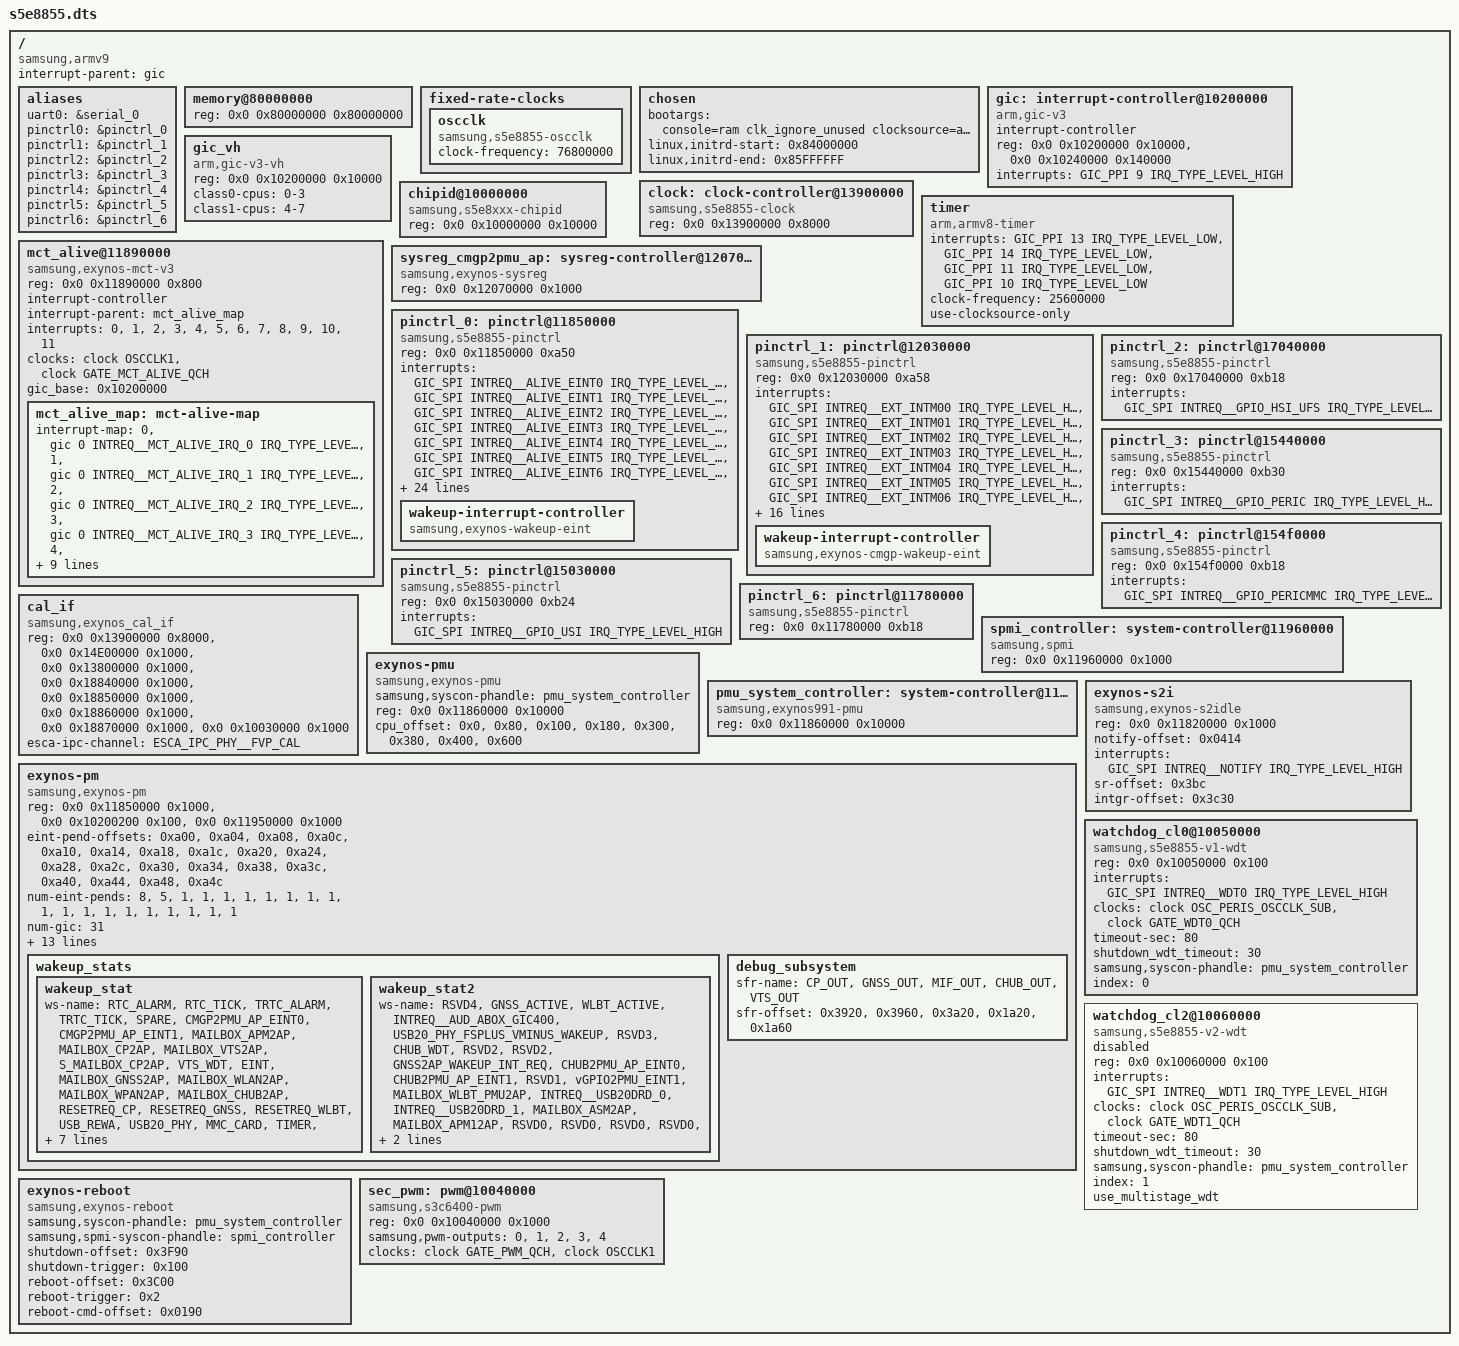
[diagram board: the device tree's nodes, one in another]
/*
 * SAMSUNG S5E8855 SoC device tree source
 *
 * Copyright (c) 2023 Samsung Electronics Co., Ltd.
 *             http://www.samsung.com
 *
 * SAMSUNG S5E8855 SoC device nodes are listed in this file.
 * EXYNOS based board files can include this file and provide
 * values for board specfic bindings.
 *
 * This program is free software; you can redistribute it and/or modify
 * it under the terms of the GNU General Public License version 2 as
 * published by the Free Software Foundation.
 */

/dts-v1/;
/plugin/;
#include <dt-bindings/clock/s5e8855.h>
#include <dt-bindings/interrupt-controller/s5e8855.h>
#include "s5e8855-pm-domains.dtsi"
#include "s5e8855-esca.dtsi"
#include <dt-bindings/soc/samsung/s5e8855-dm.h>
#include <dt-bindings/soc/samsung/s5e8855-devfreq.h>
#include <dt-bindings/soc/samsung/exynos_pm_qos.h>
//#include <dt-bindings/soc/samsung/exynos-bcm_dbg.h>
#include "s5e8855-usi.dtsi"
#include "s5e8855-pinctrl.dtsi"
#include "s5e8855-cpu.dtsi"
#include "s5e8855-ems.dtsi"
#include "s5e8855-xperf.dtsi"
#include "s5e8855-sysmmu.dtsi"
#include "s5e8855-sgpu.dtsi"
#include "s5e8855-drm-dpu.dtsi"
#include "s5e8855-usb.dtsi"
#include "s5e8855-ufs.dtsi"
#include "s5e8855-debug.dtsi"
#include "s5e8855-rmem.dtsi"
#include "s5e8855-dma-heap.dtsi"
#include "s5e8855-power.dtsi"
#include "s5e8855-security.dtsi"
#include "s5e8855-mmc.dtsi"
#include "s5e8855-m2m.dtsi"
#include "s5e8855-wlbt.dtsi"
#include "s5e8855-mfc.dtsi"
#include "s5e8855-audio.dtsi"
#include "s5e8855-chub.dtsi"
#include "s5e8855-npu.dtsi"
#include "s5e8855-camera.dtsi"
#include "s5e8855-uarch.dtsi"
#include "s5e8855-profiler.dtsi"
#include "s5e8855-mifgov.dtsi"

/ {
	compatible = "samsung,armv9", "samsung,s5e8855";
	interrupt-parent = <&gic>;
	#address-cells = <2>;
	#size-cells = <1>;

	aliases {
		uart0 = &serial_0;
		pinctrl0 = &pinctrl_0;
		pinctrl1 = &pinctrl_1;
		pinctrl2 = &pinctrl_2;
		pinctrl3 = &pinctrl_3;
		pinctrl4 = &pinctrl_4;
		pinctrl5 = &pinctrl_5;
		pinctrl6 = &pinctrl_6;
	};

	memory@80000000 {
                device_type = "memory";
                reg = <0x0 0x80000000 0x80000000>;
	};

	fixed-rate-clocks {
		oscclk {
			compatible = "samsung,s5e8855-oscclk";
			clock-frequency = <76800000>;
		};
	};

	chosen: chosen {
		bootargs = "console=ram clk_ignore_unused clocksource=arch_sys_counter printk.devkmsg=on arm64.nomte rcupdate.rcu_expedited=1 swiotlb=noforce s3c2410_wdt_ext.tmr_atboot=1 firmware_class.path=/vendor/firmware cpufreq.default_governor=energy_aware kvm-arm.protected_modules=exynos-pkvm-module,exynos-pkvm-s2mpu-module restrict_cma_redirect loop.max_part=7 memblock_memsize=procfs fault_around_bytes=32768 kswapd_cpumask=0x7f kcompactd_cpumask=0x7f raise_min_free_kbytes=false transparent_hugepage=never cgroup.memory=nokmem sgpu.gfx_timeout=10000 sgpu.mcbp=0";
		linux,initrd-start = <0x84000000>;
		linux,initrd-end = <0x85FFFFFF>;
	};

	gic:interrupt-controller@10200000 {
			compatible = "arm,gic-v3";
			#interrupt-cells = <3>;
			interrupt-controller;
			reg = <0x0 0x10200000 0x10000>,         /* GICD */
				  <0x0 0x10240000 0x140000>;        /* GICR * 10 */
			interrupts = <GIC_PPI 9 IRQ_TYPE_LEVEL_HIGH>;
	};

	gic_vh: gic_vh {
			compatible = "arm,gic-v3-vh";
			reg = <0x0 0x10200000 0x10000>;		/* GICD */
			class0-cpus = "0-3";
			class1-cpus = "4-7";
	};

	clock: clock-controller@13900000 {
		compatible = "samsung,s5e8855-clock";
		reg = <0x0 0x13900000 0x8000>;
		#clock-cells = <1>;
	};

	chipid@10000000 {
		compatible = "samsung,s5e8xxx-chipid";
		reg = <0x0 0x10000000 0x10000>;
	};

	timer {
		compatible = "arm,armv8-timer";
		interrupts = <GIC_PPI 13 IRQ_TYPE_LEVEL_LOW>,
			     <GIC_PPI 14 IRQ_TYPE_LEVEL_LOW>,
			     <GIC_PPI 11 IRQ_TYPE_LEVEL_LOW>,
			     <GIC_PPI 10 IRQ_TYPE_LEVEL_LOW>;
		clock-frequency = <25600000>;
		use-clocksource-only;
	};

	mct_alive@11890000 {
			compatible = "samsung,exynos-mct-v3";
			reg = <0x0 0x11890000 0x800>;
			interrupt-controller;
			#interrupt-cells = <1>;
			interrupt-parent = <&mct_alive_map>;
			interrupts =    <0>, <1>, <2>, <3>,
							<4>, <5>, <6>, <7>,
							<8>, <9>, <10>, <11>;
			clocks = <&clock OSCCLK1>, <&clock GATE_MCT_ALIVE_QCH>;
			clock-names = "fin_pll", "mct";
			gic_base = <0x10200000>;

			mct_alive_map: mct-alive-map {
					#interrupt-cells = <1>;
					#address-cells = <0>;
					#size-cells = <0>;
					interrupt-map = <0 &gic 0 INTREQ__MCT_ALIVE_IRQ_0 IRQ_TYPE_LEVEL_HIGH>,
							<1 &gic 0 INTREQ__MCT_ALIVE_IRQ_1 IRQ_TYPE_LEVEL_HIGH>,
							<2 &gic 0 INTREQ__MCT_ALIVE_IRQ_2 IRQ_TYPE_LEVEL_HIGH>,
							<3 &gic 0 INTREQ__MCT_ALIVE_IRQ_3 IRQ_TYPE_LEVEL_HIGH>,
							<4 &gic 0 INTREQ__MCT_ALIVE_IRQ_4 IRQ_TYPE_LEVEL_HIGH>,
							<5 &gic 0 INTREQ__MCT_ALIVE_IRQ_5 IRQ_TYPE_LEVEL_HIGH>,
							<6 &gic 0 INTREQ__MCT_ALIVE_IRQ_6 IRQ_TYPE_LEVEL_HIGH>,
							<7 &gic 0 INTREQ__MCT_ALIVE_IRQ_7 IRQ_TYPE_LEVEL_HIGH>,
							<8 &gic 0 INTREQ__MCT_ALIVE_IRQ_8 IRQ_TYPE_LEVEL_HIGH>;
			};
	};

        sysreg_cmgp2pmu_ap: sysreg-controller@12070000 {
		compatible = "samsung,exynos-sysreg", "syscon";
		reg = <0x0 0x12070000 0x1000>;
	};

	/* ALIVE */
	pinctrl_0: pinctrl@11850000 {
		compatible = "samsung,s5e8855-pinctrl";
		reg = <0x0 0x11850000 0xa50>;
		interrupts = <GIC_SPI INTREQ__ALIVE_EINT0 IRQ_TYPE_LEVEL_HIGH>,
				<GIC_SPI INTREQ__ALIVE_EINT1 IRQ_TYPE_LEVEL_HIGH>,
				<GIC_SPI INTREQ__ALIVE_EINT2 IRQ_TYPE_LEVEL_HIGH>,
				<GIC_SPI INTREQ__ALIVE_EINT3 IRQ_TYPE_LEVEL_HIGH>,
				<GIC_SPI INTREQ__ALIVE_EINT4 IRQ_TYPE_LEVEL_HIGH>,
				<GIC_SPI INTREQ__ALIVE_EINT5 IRQ_TYPE_LEVEL_HIGH>,
				<GIC_SPI INTREQ__ALIVE_EINT6 IRQ_TYPE_LEVEL_HIGH>,
				<GIC_SPI INTREQ__ALIVE_EINT7 IRQ_TYPE_LEVEL_HIGH>,
				<GIC_SPI INTREQ__ALIVE_EINT8 IRQ_TYPE_LEVEL_HIGH>,
				<GIC_SPI INTREQ__ALIVE_EINT9 IRQ_TYPE_LEVEL_HIGH>,
				<GIC_SPI INTREQ__ALIVE_EINT10 IRQ_TYPE_LEVEL_HIGH>,
				<GIC_SPI INTREQ__ALIVE_EINT11 IRQ_TYPE_LEVEL_HIGH>,
				<GIC_SPI INTREQ__ALIVE_EINT12 IRQ_TYPE_LEVEL_HIGH>,
				<GIC_SPI INTREQ__ALIVE_EXT_INTC0 IRQ_TYPE_LEVEL_HIGH>,
				<GIC_SPI INTREQ__ALIVE_EXT_INTC1 IRQ_TYPE_LEVEL_HIGH>,
				<GIC_SPI INTREQ__ALIVE_EXT_INTC2 IRQ_TYPE_LEVEL_HIGH>,
				<GIC_SPI INTREQ__ALIVE_EXT_INTC3 IRQ_TYPE_LEVEL_HIGH>,
				<GIC_SPI INTREQ__ALIVE_EXT_INTC4 IRQ_TYPE_LEVEL_HIGH>,
				<GIC_SPI INTREQ__ALIVE_EXT_INTC5 IRQ_TYPE_LEVEL_HIGH>,
				<GIC_SPI INTREQ__ALIVE_EXT_INTC6 IRQ_TYPE_LEVEL_HIGH>,
				<GIC_SPI INTREQ__ALIVE_EXT_INTC7 IRQ_TYPE_LEVEL_HIGH>,
				<GIC_SPI INTREQ__ALIVE_EXT_INTC8 IRQ_TYPE_LEVEL_HIGH>,
				<GIC_SPI INTREQ__ALIVE_EXT_INTC9 IRQ_TYPE_LEVEL_HIGH>,
				<GIC_SPI INTREQ__ALIVE_EXT_INTC10 IRQ_TYPE_LEVEL_HIGH>,
				<GIC_SPI INTREQ__ALIVE_EXT_INTC11 IRQ_TYPE_LEVEL_HIGH>,
				<GIC_SPI INTREQ__ALIVE_EXT_INTC12 IRQ_TYPE_LEVEL_HIGH>,
				<GIC_SPI INTREQ__ALIVE_EXT_INTC13 IRQ_TYPE_LEVEL_HIGH>,
				<GIC_SPI INTREQ__ALIVE_EXT_INTC14 IRQ_TYPE_LEVEL_HIGH>,
				<GIC_SPI INTREQ__ALIVE_EXT_INTC15 IRQ_TYPE_LEVEL_HIGH>,
				<GIC_SPI INTREQ__ALIVE_EXT_INTC16 IRQ_TYPE_LEVEL_HIGH>,
				<GIC_SPI INTREQ__ALIVE_EXT_INTC17 IRQ_TYPE_LEVEL_HIGH>;

		wakeup-interrupt-controller {
			compatible = "samsung,exynos-wakeup-eint";
		};
	};

	/* CMGP */
	pinctrl_1: pinctrl@12030000{
		compatible = "samsung,s5e8855-pinctrl";
		reg = <0x0 0x12030000 0xa58>;
		interrupts =
				<GIC_SPI INTREQ__EXT_INTM00 IRQ_TYPE_LEVEL_HIGH>,
				<GIC_SPI INTREQ__EXT_INTM01 IRQ_TYPE_LEVEL_HIGH>,
				<GIC_SPI INTREQ__EXT_INTM02 IRQ_TYPE_LEVEL_HIGH>,
				<GIC_SPI INTREQ__EXT_INTM03 IRQ_TYPE_LEVEL_HIGH>,
				<GIC_SPI INTREQ__EXT_INTM04 IRQ_TYPE_LEVEL_HIGH>,
				<GIC_SPI INTREQ__EXT_INTM05 IRQ_TYPE_LEVEL_HIGH>,
				<GIC_SPI INTREQ__EXT_INTM06 IRQ_TYPE_LEVEL_HIGH>,
				<GIC_SPI INTREQ__EXT_INTM07 IRQ_TYPE_LEVEL_HIGH>,
				<GIC_SPI INTREQ__EXT_INTM08 IRQ_TYPE_LEVEL_HIGH>,
				<GIC_SPI INTREQ__EXT_INTM09 IRQ_TYPE_LEVEL_HIGH>,
				<GIC_SPI INTREQ__EXT_INTM10 IRQ_TYPE_LEVEL_HIGH>,
				<GIC_SPI INTREQ__EXT_INTM11 IRQ_TYPE_LEVEL_HIGH>,
				<GIC_SPI INTREQ__EXT_INTM12 IRQ_TYPE_LEVEL_HIGH>,
				<GIC_SPI INTREQ__EXT_INTM13 IRQ_TYPE_LEVEL_HIGH>,
				<GIC_SPI INTREQ__EXT_INTM14 IRQ_TYPE_LEVEL_HIGH>,
				<GIC_SPI INTREQ__EXT_INTM15 IRQ_TYPE_LEVEL_HIGH>,
				<GIC_SPI INTREQ__EXT_INTM16 IRQ_TYPE_LEVEL_HIGH>,
				<GIC_SPI INTREQ__EXT_INTM17 IRQ_TYPE_LEVEL_HIGH>,
				<GIC_SPI INTREQ__EXT_INTM18 IRQ_TYPE_LEVEL_HIGH>,
				<GIC_SPI INTREQ__EXT_INTM19 IRQ_TYPE_LEVEL_HIGH>,
				<GIC_SPI INTREQ__EXT_INTM20 IRQ_TYPE_LEVEL_HIGH>,
				<GIC_SPI INTREQ__EXT_INTM21 IRQ_TYPE_LEVEL_HIGH>;

		samsung,syscon-phandle = <&sysreg_cmgp2pmu_ap>;
		wakeup-interrupt-controller {
			compatible = "samsung,exynos-cmgp-wakeup-eint";
		};
	};

	/* HSIUFS */
	pinctrl_2: pinctrl@17040000 {
		compatible = "samsung,s5e8855-pinctrl";
		reg = <0x0 0x17040000 0xb18>;
		interrupts = <GIC_SPI INTREQ__GPIO_HSI_UFS IRQ_TYPE_LEVEL_HIGH>;
	};

	/* PERIC */
	pinctrl_3: pinctrl@15440000 {
		compatible = "samsung,s5e8855-pinctrl";
		reg = <0x0 0x15440000 0xb30>;
		interrupts = <GIC_SPI INTREQ__GPIO_PERIC IRQ_TYPE_LEVEL_HIGH>;
	};

	/* PERICMMC */
	pinctrl_4: pinctrl@154f0000 {
		compatible = "samsung,s5e8855-pinctrl";
		reg = <0x0 0x154f0000 0xb18>;
		interrupts = <GIC_SPI INTREQ__GPIO_PERICMMC IRQ_TYPE_LEVEL_HIGH>;
	};

	/* USI */
	pinctrl_5: pinctrl@15030000 {
		compatible = "samsung,s5e8855-pinctrl";
		reg = <0x0 0x15030000 0xb24>;
		interrupts = <GIC_SPI INTREQ__GPIO_USI IRQ_TYPE_LEVEL_HIGH>;
	};

	/* VTS */
	pinctrl_6: pinctrl@11780000 {
		compatible = "samsung,s5e8855-pinctrl";
		reg = <0x0 0x11780000 0xb18>;
		/*
		 * pinctrl framework will not support VTS GPIO Interrupt.
		 * VTS subsystem has to take care for it.
		 */
	};

	/*CAL-IF*/
	cal_if {
		compatible = "samsung,exynos_cal_if";
		reg = <0x0 0x13900000 0x8000>, /* CMU_TOP */
				<0x0 0x14E00000 0x1000>, /* CMU_AUD */
				<0x0 0x13800000 0x1000>, /* CMU_NOCL0 */
				<0x0 0x18840000 0x1000>, /* CMU_CPUCL0 */
				<0x0 0x18850000 0x1000>, /* CMU_CPUCL1 */
				<0x0 0x18860000 0x1000>, /* CMU_CPUCL2 */
				<0x0 0x18870000 0x1000>, /* CMU_DSU */
				<0x0 0x10030000 0x1000>; /* CMU_PERIS */
		esca-ipc-channel = <ESCA_IPC_PHY__FVP_CAL>;
	};

	spmi_controller: system-controller@11960000 {
		compatible = "samsung,spmi", "syscon";
		reg = <0x0 0x11960000 0x1000>;
	};

	/* PMU */
	exynos-pmu {
		compatible = "samsung,exynos-pmu";
		samsung,syscon-phandle = <&pmu_system_controller>;
		reg = <0x0 0x11860000 0x10000>;
		reg-names = "pmu_alive";
		cpu_offset = <0x0>, <0x80>, <0x100>, <0x180>,
					<0x300>, <0x380>, <0x400>, <0x600>;
	};

	pmu_system_controller: system-controller@11860000 {
		compatible = "samsung,exynos991-pmu", "syscon";
		reg = <0x0 0x11860000 0x10000>;
	};

	exynos-s2i {
		compatible = "samsung,exynos-s2idle";
		reg = <0x0 0x11820000 0x1000>;
		reg-names = "sysreg_alive";
		notify-offset = <0x0414>;       /* SYSREG_ALIVE NOTIFY offset */
		interrupts = <GIC_SPI INTREQ__NOTIFY IRQ_TYPE_LEVEL_HIGH>;      /* SYSREG_ALIVE NOTIFY */
		sr-offset = <0x3bc>;            /* PMU_SPARE7 */
		intgr-offset = <0x3c30>;        /* PMU_SPARE_CTRL */
	};

	exynos-pm {
		compatible = "samsung,exynos-pm";
	        reg = <0x0 0x11850000 0x1000>,
			<0x0 0x10200200 0x100>,
			<0x0 0x11950000 0x1000>;
		reg-names = "gpio_alive_base",
			"gicd_ispendrn_base",
			"sysreg_vgpio2pmu";

		eint-pend-offsets = <0xa00>, <0xa04>, <0xa08>, <0xa0c>, <0xa10>, <0xa14>,
			<0xa18>, <0xa1c>, <0xa20>, <0xa24>, <0xa28>, <0xa2c>, <0xa30>,
			<0xa34>, <0xa38>, <0xa3c>, <0xa40>, <0xa44>, <0xa48>, <0xa4c>;
		num-eint-pends = <8>, <5>, <1>, <1>, <1>, <1>,
			<1>, <1>, <1>, <1>, <1>, <1>, <1>,
			<1>, <1>, <1>, <1>, <1>, <1>, <1>;
		num-gic = <31>;
		suspend_mode_idx = <8>;         /* SYS_SLEEP */

		/* WAKEUP_STAT,      WAKEUP2_STAT*/
		wakeup_stat_offset = <0x3b50>,         <0x3b54>;
		wakeup_int_en_offset = <0x3b44>,         <0x3b64>;
		wakeup_int_en = <0x001fff6f>,         <0xe258>;
		usbl2_wakeup_int_en = <0x0>, <0x10>;
		eint_wakeup_mask_offset = <0x3e40>;
		wakeup-stat-eint = <12>;
		wakeup-stat-rtc = <0>;

		vgpio_wakeup_inten = <0x8c0>;
		vgpio_wakeup_inten_offset = <0x288>;

		wake_lock = <0>;                /* 1: held wake_lock */

		pcieon_suspend_available = <1>;
		pcieon_suspend_mode_idx = <13>;  /* SYS_SLEEP_HSI1ON */

		wakeup_stats {
			wakeup_stat {
				ws-name =
					"RTC_ALARM",                    /* [0] */
					"RTC_TICK",                     /* [1] */
					"TRTC_ALARM",                   /* [2] */
					"TRTC_TICK",                    /* [3] */
					"SPARE",                        /* [4] */
					"CMGP2PMU_AP_EINT0",            /* [5] */
					"CMGP2PMU_AP_EINT1",            /* [6] */
					"MAILBOX_APM2AP",               /* [7] */
					"MAILBOX_CP2AP",                /* [8] */
					"MAILBOX_VTS2AP",               /* [9] */
					"S_MAILBOX_CP2AP",              /* [10] */
					"VTS_WDT",                      /* [11] */
					"EINT",                         /* [12] */
					"MAILBOX_GNSS2AP",              /* [13] */
					"MAILBOX_WLAN2AP",              /* [14] */
					"MAILBOX_WPAN2AP",              /* [15] */
					"MAILBOX_CHUB2AP",              /* [16] */
					"RESETREQ_CP",                  /* [17] */
					"RESETREQ_GNSS",                /* [18] */
					"RESETREQ_WLBT",                /* [19] */
					"USB_REWA",                     /* [20] */
					"USB20_PHY",                    /* [21] */
					"MMC_CARD",                     /* [22] */
					"TIMER",                        /* [23] */
					"CLUSTER0_CPU0_nIRQOUT",        /* [24] */
					"CLUSTER0_CPU1_nIRQOUT",        /* [25] */
					"CLUSTER0_CPU2_nIRQOUT",        /* [26] */
					"CLUSTER0_CPU3_nIRQOUT",        /* [27] */
					"CLUSTER1_CPU0_nIRQOUT",        /* [28] */
					"CLUSTER1_CPU1_nIRQOUT",        /* [29] */
					"CLUSTER1_CPU2_nIRQOUT",        /* [30] */
					"CLUSTER2_CPU0_nIRQOUT";        /* [31] */

			};

			wakeup_stat2 {
				ws-name =
					"RSVD4",                        /* [0] */
					"GNSS_ACTIVE",                  /* [1] */
					"WLBT_ACTIVE",                  /* [2] */
					"INTREQ__AUD_ABOX_GIC400",      /* [3] */
					"USB20_PHY_FSPLUS_VMINUS_WAKEUP",/* [4] */
					"RSVD3",                        /* [5] */
					"CHUB_WDT",                     /* [6] */
					"RSVD2",                        /* [7] */
					"RSVD2",                        /* [8] */
					"GNSS2AP_WAKEUP_INT_REQ",       /* [9] */
					"CHUB2PMU_AP_EINT0",            /* [10] */
					"CHUB2PMU_AP_EINT1",            /* [11] */
					"RSVD1",                        /* [12] */
					"vGPIO2PMU_EINT1",              /* [13] */
					"MAILBOX_WLBT_PMU2AP",          /* [14] */
					"INTREQ__USB20DRD_0",           /* [15] */
					"INTREQ__USB20DRD_1",           /* [16] */
					"MAILBOX_ASM2AP",               /* [17] */
					"MAILBOX_APM12AP",              /* [18] */
					"RSVD0",                        /* [19] */
					"RSVD0",                        /* [20] */
					"RSVD0",                        /* [21] */
					"RSVD0",                        /* [22] */
					"RSVD0",                        /* [23] */
					"RSVD0",                        /* [24] */
					"RSVD0",                        /* [25] */
					"RSVD0",                        /* [26] */
					"RSVD0",                        /* [27] */
					"RSVD0",                        /* [28] */
					"RSVD0",                        /* [29] */
					"RSVD0",                        /* [30] */
					"RSVD0";                        /* [31] */
			};
		};

			debug_subsystem {
			sfr-name =
				"CP_OUT",
				"GNSS_OUT",
				"MIF_OUT",
				"CHUB_OUT",
				"VTS_OUT";
			sfr-offset =
				<0x3920>,
				<0x3960>,
				<0x3a20>,
				<0x1a20>,
				<0x1a60>;
		};
	};



	watchdog_cl0@10050000 {
		compatible = "samsung,s5e8855-v1-wdt";
		reg = <0x0 0x10050000 0x100>;
		interrupts = <GIC_SPI INTREQ__WDT0 IRQ_TYPE_LEVEL_HIGH>;
		clocks = <&clock OSC_PERIS_OSCCLK_SUB>, <&clock GATE_WDT0_QCH>;
		clock-names = "rate_watchdog", "gate_watchdog";
		timeout-sec = <80>;
		shutdown_wdt_timeout = <30>;
		samsung,syscon-phandle = <&pmu_system_controller>;
		index = <0>; /* if little cluster then index is 0 */
		status = "okay";
	};

	watchdog_cl2@10060000 {
		compatible = "samsung,s5e8855-v2-wdt";
		reg = <0x0 0x10060000 0x100>;
		interrupts = <GIC_SPI INTREQ__WDT1 IRQ_TYPE_LEVEL_HIGH>;
		clocks = <&clock OSC_PERIS_OSCCLK_SUB>, <&clock GATE_WDT1_QCH>;
		clock-names = "rate_watchdog", "gate_watchdog";
		timeout-sec = <80>;
		shutdown_wdt_timeout = <30>;
		samsung,syscon-phandle = <&pmu_system_controller>;
		index = <1>; /* if big cluster then index is 1 */
		use_multistage_wdt;
		status = "disabled";
	};

	exynos-reboot {
		compatible = "samsung,exynos-reboot";
		samsung,syscon-phandle = <&pmu_system_controller>;
		samsung,spmi-syscon-phandle = <&spmi_controller>;
		shutdown-offset = <0x3F90>;
		shutdown-trigger = <0x100>;
		reboot-offset = <0x3C00>;
		reboot-trigger = <0x2>;
		reboot-cmd-offset = <0x0190>;
		status = "okay";
	};

	sec_pwm: pwm@10040000 {
			compatible = "samsung,s3c6400-pwm";
			reg = <0x0 0x10040000 0x1000>;
			samsung,pwm-outputs = <0>, <1>, <2>, <3>, <4>;
			#pwm-cells = <3>;
			clocks = <&clock GATE_PWM_QCH>, <&clock OSCCLK1>;
			clock-names = "pwm_pclk", "pwm_sclk";
			status = "okay";
	};
};
